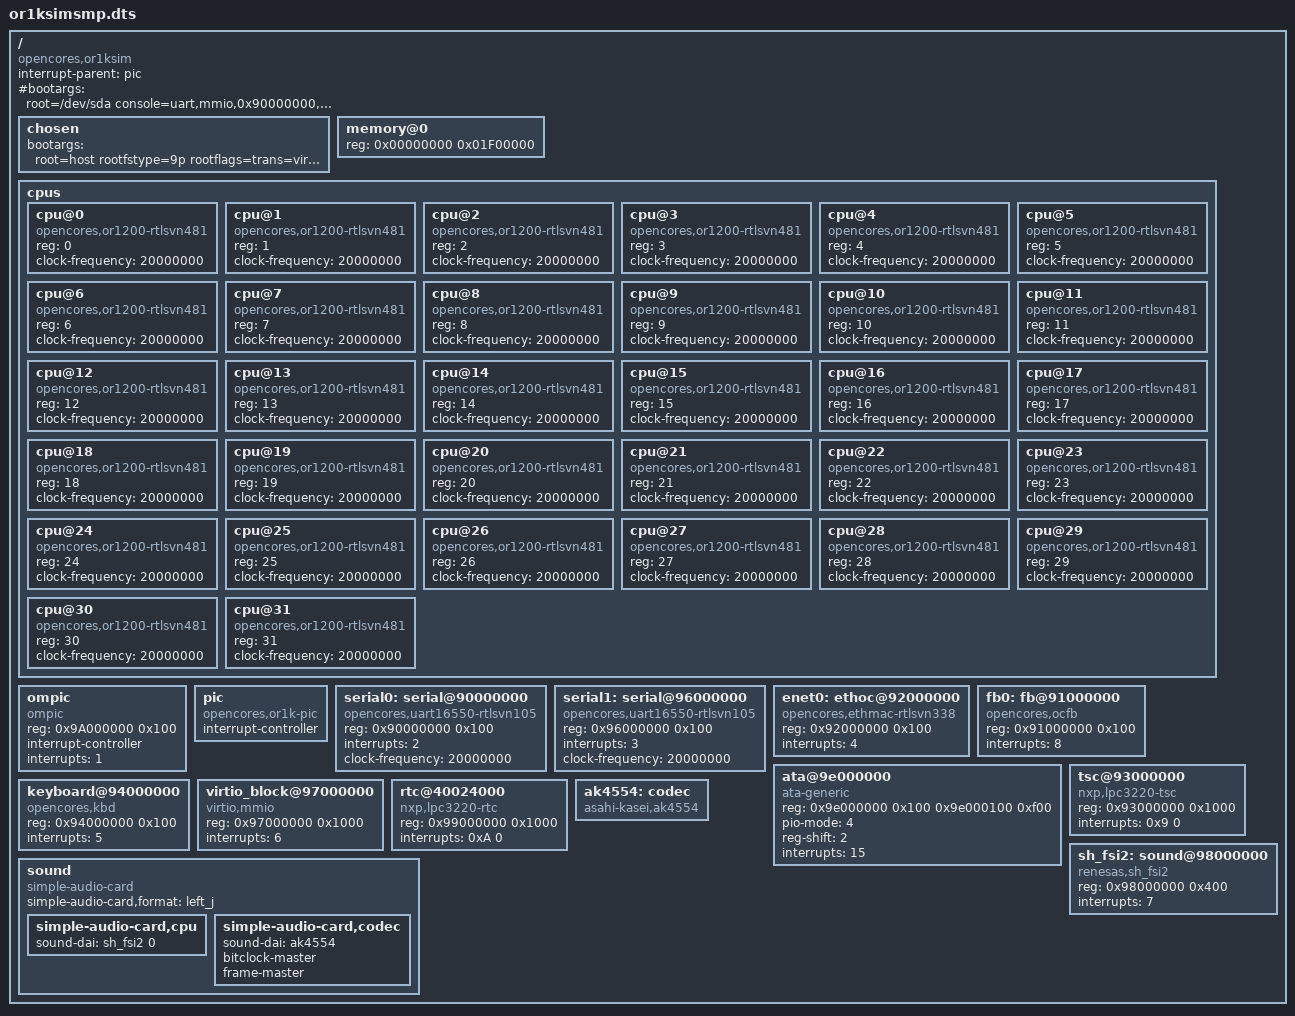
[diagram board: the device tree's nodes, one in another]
/dts-v1/;
/ {
	compatible = "opencores,or1ksim";
	#address-cells = <1>;
	#size-cells = <1>;
	interrupt-parent = <&pic>;
	#bootargs = "root=/dev/sda console=uart,mmio,0x90000000,115200 video=ocfb:mode_option=640x400-32";

	chosen {
		bootargs = "root=host rootfstype=9p rootflags=trans=virtio console=uart,mmio,0x90000000,115200 video=ocfb:mode_option=640x400-16";
	};

	memory@0 {
		device_type = "memory";
		reg = <0x00000000 0x01F00000>;
	};

	cpus {
		#address-cells = <1>;
		#size-cells = <0>;
		cpu@0 {
			compatible = "opencores,or1200-rtlsvn481";
			reg = <0>;
			clock-frequency = <20000000>;
		};
		cpu@1 {
			compatible = "opencores,or1200-rtlsvn481";
			reg = <1>;
			clock-frequency = <20000000>;
		};
		cpu@2 {
			compatible = "opencores,or1200-rtlsvn481";
			reg = <2>;
			clock-frequency = <20000000>;
		};
		cpu@3 {
			compatible = "opencores,or1200-rtlsvn481";
			reg = <3>;
			clock-frequency = <20000000>;
		};
		cpu@4 {
			compatible = "opencores,or1200-rtlsvn481";
			reg = <4>;
			clock-frequency = <20000000>;
		};
		cpu@5 {
			compatible = "opencores,or1200-rtlsvn481";
			reg = <5>;
			clock-frequency = <20000000>;
		};
		cpu@6 {
			compatible = "opencores,or1200-rtlsvn481";
			reg = <6>;
			clock-frequency = <20000000>;
		};
		cpu@7 {
			compatible = "opencores,or1200-rtlsvn481";
			reg = <7>;
			clock-frequency = <20000000>;
		};
		cpu@8 {
			compatible = "opencores,or1200-rtlsvn481";
			reg = <8>;
			clock-frequency = <20000000>;
		};
		cpu@9 {
			compatible = "opencores,or1200-rtlsvn481";
			reg = <9>;
			clock-frequency = <20000000>;
		};
		cpu@10 {
			compatible = "opencores,or1200-rtlsvn481";
			reg = <10>;
			clock-frequency = <20000000>;
		};
		cpu@11 {
			compatible = "opencores,or1200-rtlsvn481";
			reg = <11>;
			clock-frequency = <20000000>;
		};
		cpu@12 {
			compatible = "opencores,or1200-rtlsvn481";
			reg = <12>;
			clock-frequency = <20000000>;
		};
		cpu@13 {
			compatible = "opencores,or1200-rtlsvn481";
			reg = <13>;
			clock-frequency = <20000000>;
		};
		cpu@14 {
			compatible = "opencores,or1200-rtlsvn481";
			reg = <14>;
			clock-frequency = <20000000>;
		};
		cpu@15 {
			compatible = "opencores,or1200-rtlsvn481";
			reg = <15>;
			clock-frequency = <20000000>;
		};
		cpu@16 {
			compatible = "opencores,or1200-rtlsvn481";
			reg = <16>;
			clock-frequency = <20000000>;
		};
		cpu@17 {
			compatible = "opencores,or1200-rtlsvn481";
			reg = <17>;
			clock-frequency = <20000000>;
		};
		cpu@18 {
			compatible = "opencores,or1200-rtlsvn481";
			reg = <18>;
			clock-frequency = <20000000>;
		};
		cpu@19 {
			compatible = "opencores,or1200-rtlsvn481";
			reg = <19>;
			clock-frequency = <20000000>;
		};
		cpu@20 {
			compatible = "opencores,or1200-rtlsvn481";
			reg = <20>;
			clock-frequency = <20000000>;
		};
		cpu@21 {
			compatible = "opencores,or1200-rtlsvn481";
			reg = <21>;
			clock-frequency = <20000000>;
		};
		cpu@22 {
			compatible = "opencores,or1200-rtlsvn481";
			reg = <22>;
			clock-frequency = <20000000>;
		};
		cpu@23 {
			compatible = "opencores,or1200-rtlsvn481";
			reg = <23>;
			clock-frequency = <20000000>;
		};
		cpu@24 {
			compatible = "opencores,or1200-rtlsvn481";
			reg = <24>;
			clock-frequency = <20000000>;
		};
		cpu@25 {
			compatible = "opencores,or1200-rtlsvn481";
			reg = <25>;
			clock-frequency = <20000000>;
		};
		cpu@26 {
			compatible = "opencores,or1200-rtlsvn481";
			reg = <26>;
			clock-frequency = <20000000>;
		};
		cpu@27 {
			compatible = "opencores,or1200-rtlsvn481";
			reg = <27>;
			clock-frequency = <20000000>;
		};
		cpu@28 {
			compatible = "opencores,or1200-rtlsvn481";
			reg = <28>;
			clock-frequency = <20000000>;
		};
		cpu@29 {
			compatible = "opencores,or1200-rtlsvn481";
			reg = <29>;
			clock-frequency = <20000000>;
		};
		cpu@30 {
			compatible = "opencores,or1200-rtlsvn481";
			reg = <30>;
			clock-frequency = <20000000>;
		};
		cpu@31 {
			compatible = "opencores,or1200-rtlsvn481";
			reg = <31>;
			clock-frequency = <20000000>;
		};
	};

        /* 
         * If ompic is compiled in, it will used as default
         */
	ompic: ompic {
		compatible = "ompic";
		reg = <0x9A000000 0x100>;
		#interrupt-cells = <1>;
		interrupt-controller;
		interrupts = <1>;
	};

	/*
	 * OR1K PIC is built into CPU and accessed via special purpose
	 * registers.  It is not addressable and, hence, has no 'reg'
	 * property.
	 */
	pic: pic {
		compatible = "opencores,or1k-pic";
		#interrupt-cells = <1>;
		interrupt-controller;
	};

	serial0: serial@90000000 {
		compatible = "opencores,uart16550-rtlsvn105", "ns16550a";
		reg = <0x90000000 0x100>;
		interrupts = <2>;
		clock-frequency = <20000000>;
	};

	serial1: serial@96000000 {
		compatible = "opencores,uart16550-rtlsvn105", "ns16550a";
		reg = <0x96000000 0x100>;
		interrupts = <3>;
		clock-frequency = <20000000>;
	};

	enet0: ethoc@92000000 {
		compatible = "opencores,ethmac-rtlsvn338";
		reg = <0x92000000 0x100>;
		interrupts = <4>;
	};

        fb0: fb@91000000 {
                compatible = "opencores,ocfb";
                reg = <0x91000000 0x100>;
                interrupts = <8>;
        };

/*
        mtd0: flash@95000000 {
                device_type="rom";
                compatible = "direct-mapped";
                reg = <0x95000000 0x02000000>;
                bank-width = <1>;
                read-only;
        };
*/
	
	ata@9e000000  {
		compatible = "ata-generic";
                reg = <0x9e000000 0x100
		       0x9e000100 0xf00>;
		pio-mode = <4>;
		reg-shift = <2>;
                interrupts = <15>;
	};

	tsc@93000000 {
		compatible = "nxp,lpc3220-tsc";
		reg = <0x93000000 0x1000>;
		interrupts = <0x9 0>;
	};

	keyboard@94000000 {
		compatible = "opencores,kbd";
		reg = <0x94000000 0x100>;
		interrupts = <5>;
	};

        virtio_block@97000000 {
                compatible = "virtio,mmio";
                reg = <0x97000000 0x1000>;
                interrupts = <6>;
        };

        rtc@40024000 {
                compatible = "nxp,lpc3220-rtc";
                reg = <0x99000000 0x1000>;
                interrupts = <0xA 0>;
        };

	sh_fsi2: sound@98000000 {
		#sound-dai-cells = <1>;
		compatible = "renesas,sh_fsi2";
		reg = <0x98000000 0x400>;
		interrupts = <7>;
	};

	ak4554: codec {
		#sound-dai-cells = <0>;
		compatible = "asahi-kasei,ak4554";
	};

        sound {
                compatible = "simple-audio-card";
                simple-audio-card,format = "left_j";
                simple-audio-card,cpu {
                        sound-dai = <&sh_fsi2 0>;
                };
                simple-audio-card,codec {
                        sound-dai = <&ak4554>;
                        bitclock-master;
                        frame-master;
                        /*system-clock-frequency = <11289600>;*/
                };
        };


};
